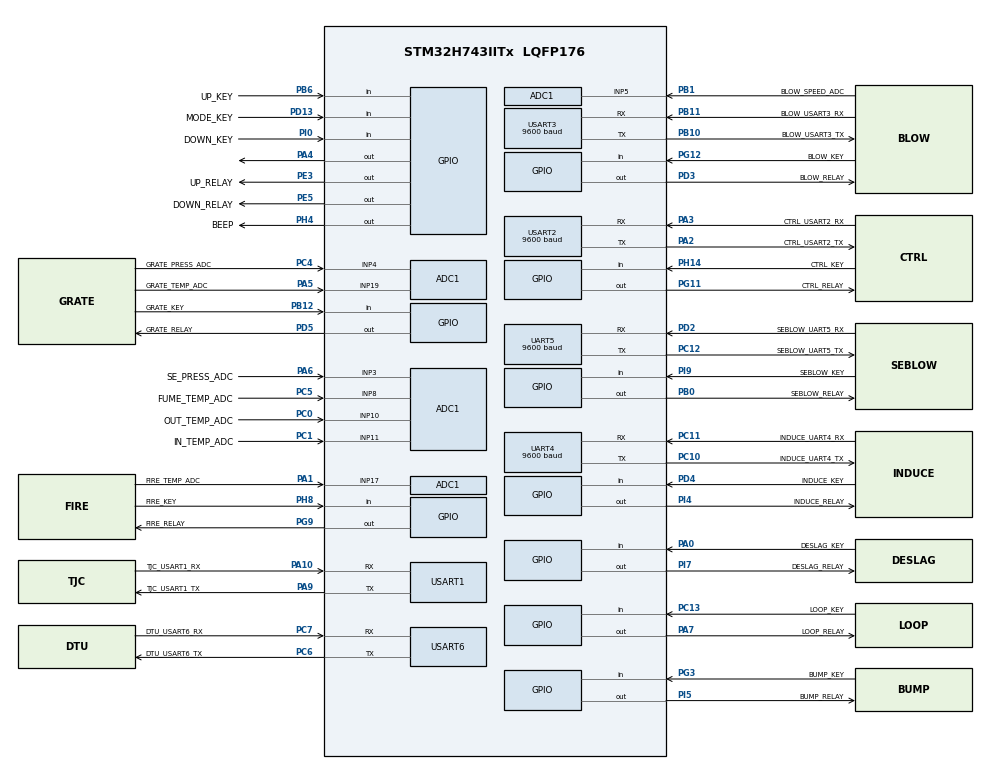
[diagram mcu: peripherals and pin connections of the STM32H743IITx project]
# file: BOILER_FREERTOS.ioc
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ADC1.Channel-0\#ChannelRegularConversion=ADC_CHANNEL_11
ADC1.NbrOfConversionFlag=1
ADC1.OffsetNumber-0\#ChannelRegularConversion=ADC_OFFSET_NONE
ADC1.OffsetSignedSaturation-0\#ChannelRegularConversion=DISABLE
ADC1.Rank-0\#ChannelRegularConversion=1
ADC1.SamplingTime-0\#ChannelRegularConversion=ADC_SAMPLETIME_1CYCLE_5
ADC1.master=1
CORTEX_M7.default_mode_Activation=1
Mcu.Family=STM32H7
Mcu.Name=STM32H743IITx
Mcu.Package=LQFP176
NVIC.PriorityGroup=NVIC_PRIORITYGROUP_4
NVIC.TIM4_IRQn=true\:15\:0\:false\:false\:true\:false\:true\:true
NVIC.TimeBase=TIM4_IRQn
NVIC.TimeBaseIP=TIM4
PA0.GPIO_Label=DESLAG_KEY
PA0.GPIO_PuPd=GPIO_PULLUP
PA0.Signal=GPIO_Input
PA1.GPIO_Label=FIRE_TEMP_ADC
PA1.Mode=IN17-Single-Ended
PA1.Signal=ADC1_INP17
PA10.GPIO_Label=TJC_USART1_RX
PA10.Mode=Asynchronous
PA10.Signal=USART1_RX
PA13\ (JTMS/SWDIO).Mode=Serial_Wire
PA13\ (JTMS/SWDIO).Signal=DEBUG_JTMS-SWDIO
PA14\ (JTCK/SWCLK).Mode=Serial_Wire
PA14\ (JTCK/SWCLK).Signal=DEBUG_JTCK-SWCLK
PA2.GPIO_Label=CTRL_USART2_TX
PA2.Mode=Asynchronous
PA2.Signal=USART2_TX
PA3.GPIO_Label=CTRL_USART2_RX
PA3.Mode=Asynchronous
PA3.Signal=USART2_RX
PA4.Signal=GPIO_Output
PA5.GPIO_Label=GRATE_TEMP_ADC
PA5.Signal=ADCx_INP19
PA6.GPIO_Label=SE_PRESS_ADC
PA6.Signal=ADCx_INP3
PA7.GPIO_Label=LOOP_RELAY
PA7.GPIO_PuPd=GPIO_PULLDOWN
PA7.Signal=GPIO_Output
PA9.GPIO_Label=TJC_USART1_TX
PA9.Mode=Asynchronous
PA9.Signal=USART1_TX
PB0.GPIO_Label=SEBLOW_RELAY
PB0.GPIO_PuPd=GPIO_PULLDOWN
PB0.Signal=GPIO_Output
PB1.GPIO_Label=BLOW_SPEED_ADC
PB1.Signal=ADCx_INP5
PB10.GPIO_Label=BLOW_USART3_TX
PB10.Mode=Asynchronous
PB10.Signal=USART3_TX
PB11.GPIO_Label=BLOW_USART3_RX
PB11.Mode=Asynchronous
PB11.Signal=USART3_RX
PB12.GPIO_Label=GRATE_KEY
PB12.GPIO_PuPd=GPIO_PULLUP
PB12.Signal=GPIO_Input
PB6.GPIO_Label=UP_KEY
PB6.GPIO_PuPd=GPIO_PULLUP
PB6.Signal=GPIO_Input
PB8.GPIO_Label=AT24CXX_SCL
PB8.Signal=I2C1_SCL
PB9.GPIO_Label=AT24CXX_SDA
PB9.Signal=I2C1_SDA
PC0.GPIO_Label=OUT_TEMP_ADC
PC0.Signal=ADCx_INP10
PC1.GPIO_Label=IN_TEMP_ADC
PC1.Signal=ADCx_INP11
PC10.GPIO_Label=INDUCE_UART4_TX
PC10.Mode=Asynchronous
PC10.Signal=UART4_TX
PC11.GPIO_Label=INDUCE_UART4_RX
PC11.Mode=Asynchronous
PC11.Signal=UART4_RX
PC12.GPIO_Label=SEBLOW_UART5_TX
PC12.Mode=Asynchronous
PC12.Signal=UART5_TX
PC13.GPIO_Label=LOOP_KEY
PC13.GPIO_PuPd=GPIO_PULLUP
PC13.Signal=GPIO_Input
PC14-OSC32_IN\ (OSC32_IN).Mode=LSE-External-Oscillator
PC14-OSC32_IN\ (OSC32_IN).Signal=RCC_OSC32_IN
PC15-OSC32_OUT\ (OSC32_OUT).Mode=LSE-External-Oscillator
PC15-OSC32_OUT\ (OSC32_OUT).Signal=RCC_OSC32_OUT
PC4.GPIO_Label=GRATE_PRESS_ADC
PC4.Signal=ADCx_INP4
PC5.GPIO_Label=FUME_TEMP_ADC
PC5.Signal=ADCx_INP8
PC6.GPIO_Label=DTU_USART6_TX
PC6.Mode=Asynchronous
PC6.Signal=USART6_TX
PC7.GPIO_Label=DTU_USART6_RX
PC7.Mode=Asynchronous
PC7.Signal=USART6_RX
PD13.GPIO_Label=MODE_KEY
PD13.GPIO_PuPd=GPIO_PULLUP
PD13.Signal=GPIO_Input
PD2.GPIO_Label=SEBLOW_UART5_RX
PD2.Mode=Asynchronous
PD2.Signal=UART5_RX
PD3.GPIO_Label=BLOW_RELAY
PD3.GPIO_PuPd=GPIO_PULLDOWN
PD3.Signal=GPIO_Output
PD4.GPIO_Label=INDUCE_KEY
PD4.GPIO_PuPd=GPIO_PULLUP
PD4.Signal=GPIO_Input
PD5.GPIO_Label=GRATE_RELAY
PD5.GPIO_PuPd=GPIO_PULLDOWN
PD5.Signal=GPIO_Output
PE3.GPIO_Label=UP_RELAY
PE3.GPIO_PuPd=GPIO_PULLDOWN
PE3.Signal=GPIO_Output
PE5.GPIO_Label=DOWN_RELAY
PE5.GPIO_PuPd=GPIO_PULLDOWN
PE5.Signal=GPIO_Output
PG11.GPIO_Label=CTRL_RELAY
PG11.GPIO_PuPd=GPIO_PULLDOWN
PG11.Signal=GPIO_Output
PG12.GPIO_Label=BLOW_KEY
PG12.GPIO_PuPd=GPIO_PULLUP
PG12.Signal=GPIO_Input
PG3.GPIO_Label=BUMP_KEY
PG3.GPIO_PuPd=GPIO_PULLUP
PG3.Signal=GPIO_Input
PG9.GPIO_Label=FIRE_RELAY
PG9.GPIO_PuPd=GPIO_PULLDOWN
PG9.Signal=GPIO_Output
PH0-OSC_IN\ (PH0).Mode=HSE-External-Oscillator
PH0-OSC_IN\ (PH0).Signal=RCC_OSC_IN
PH1-OSC_OUT\ (PH1).Mode=HSE-External-Oscillator
PH1-OSC_OUT\ (PH1).Signal=RCC_OSC_OUT
PH14.GPIO_Label=CTRL_KEY
PH14.GPIO_PuPd=GPIO_PULLUP
PH14.Signal=GPIO_Input
PH4.GPIO_Label=BEEP
PH4.GPIO_PuPd=GPIO_PULLDOWN
PH4.GPIO_Speed=GPIO_SPEED_FREQ_MEDIUM
PH4.Signal=GPIO_Output
PH8.GPIO_Label=FIRE_KEY
PH8.GPIO_PuPd=GPIO_PULLUP
PH8.Signal=GPIO_Input
PI0.GPIO_Label=DOWN_KEY
PI0.GPIO_PuPd=GPIO_PULLUP
PI0.Signal=GPIO_Input
PI4.GPIO_Label=INDUCE_RELAY
PI4.GPIO_PuPd=GPIO_PULLDOWN
PI4.Signal=GPIO_Output
PI5.GPIO_Label=BUMP_RELAY
PI5.GPIO_PuPd=GPIO_PULLDOWN
PI5.Signal=GPIO_Output
PI7.GPIO_Label=DESLAG_RELAY
PI7.GPIO_PuPd=GPIO_PULLDOWN
PI7.Signal=GPIO_Output
PI9.GPIO_Label=SEBLOW_KEY
PI9.GPIO_PuPd=GPIO_PULLUP
PI9.Signal=GPIO_Input
ProjectManager.HeapSize=0x200
ProjectManager.StackSize=0x400
ProjectManager.TargetToolchain=MDK-ARM V5.32
RCC.ADCFreq_Value=75000000
RCC.APB1Freq_Value=100000000
RCC.APB2Freq_Value=100000000
RCC.APB3Freq_Value=100000000
RCC.APB4Freq_Value=100000000
RCC.CortexFreq_Value=400000000
RCC.D1PPRE=RCC_APB3_DIV2
RCC.D2PPRE1=RCC_APB1_DIV2
RCC.D2PPRE2=RCC_APB2_DIV2
RCC.D3PPRE=RCC_APB4_DIV2
RCC.DIVM1=2
RCC.DIVM2=2
RCC.DIVN1=64
RCC.DIVN2=12
RCC.HCLKFreq_Value=200000000
RCC.HPRE=RCC_HCLK_DIV2
RCC.PLL2FRACN=0
RCC.PLLFRACN=0
RCC.PLLSourceVirtual=RCC_PLLSOURCE_HSE
RCC.SYSCLKFreq_VALUE=400000000
RCC.SYSCLKSource=RCC_SYSCLKSOURCE_PLLCLK
RCC.USBFreq_Value=400000000
SH.ADCx_INP10.0=ADC1_INP10,IN10-Single-Ended
SH.ADCx_INP11.0=ADC1_INP11,IN11-Single-Ended
SH.ADCx_INP19.0=ADC1_INP19,IN19-Single-Ended
SH.ADCx_INP3.0=ADC1_INP3,IN3-Single-Ended
SH.ADCx_INP4.0=ADC1_INP4,IN4-Single-Ended
SH.ADCx_INP5.0=ADC1_INP5,IN5-Single-Ended
SH.ADCx_INP8.0=ADC1_INP8,IN8-Single-Ended
UART4.BaudRate=9600
UART5.BaudRate=9600
USART1.VirtualMode-Asynchronous=VM_ASYNC
USART2.BaudRate=9600
USART2.VirtualMode-Asynchronous=VM_ASYNC
USART3.BaudRate=9600
USART3.VirtualMode-Asynchronous=VM_ASYNC
USART6.VirtualMode-Asynchronous=VM_ASYNC
VP_MEMORYMAP_VS_MEMORYMAP.Mode=CurAppReg
VP_SYS_VS_tim4.Mode=TIM4
board=custom

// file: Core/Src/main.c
/* USER CODE BEGIN Header */
/**
  ******************************************************************************
  * @file           : main.c
  * @brief          : Main program body
  ******************************************************************************
  * @attention
  *
  * Copyright (c) 2026 STMicroelectronics.
  * All rights reserved.
  *
  * This software is licensed under terms that can be found in the LICENSE file
  * in the root directory of this software component.
  * If no LICENSE file comes with this software, it is provided AS-IS.
  *
  ******************************************************************************
  */
/* USER CODE END Header */
#include "main.h"
#include "adc.h"
#include "memorymap.h"
#include "usart.h"
#include "gpio.h"

/* USER CODE BEGIN Includes */
#include "app_freertos.h"
/* USER CODE END Includes */

void SystemClock_Config(void);
static void MPU_Config(void);

int main(void)
{

  /* MPU Configuration--------------------------------------------------------*/
  MPU_Config();

  /* MCU Configuration--------------------------------------------------------*/

  /* Reset of all peripherals, Initializes the Flash interface and the Systick. */
  HAL_Init();

  /* Configure the system clock */
  SystemClock_Config();

  /* Initialize all configured peripherals */
  MX_GPIO_Init();
  MX_ADC1_Init();
  MX_UART4_Init();
  MX_UART5_Init();
  MX_USART1_UART_Init();
  MX_USART2_UART_Init();
  MX_USART3_UART_Init();
  MX_USART6_UART_Init();

  /* Infinite loop */
  while (1)
  {

  }
}

void SystemClock_Config(void)
{
  RCC_OscInitTypeDef RCC_OscInitStruct = {0};
  RCC_ClkInitTypeDef RCC_ClkInitStruct = {0};

  /** Supply configuration update enable
  */
  HAL_PWREx_ConfigSupply(PWR_LDO_SUPPLY);

  /** Configure the main internal regulator output voltage
  */
  __HAL_PWR_VOLTAGESCALING_CONFIG(PWR_REGULATOR_VOLTAGE_SCALE1);

  while(!__HAL_PWR_GET_FLAG(PWR_FLAG_VOSRDY)) {}

  /** Initializes the RCC Oscillators according to the specified parameters
  * in the RCC_OscInitTypeDef structure.
  */
  RCC_OscInitStruct.OscillatorType = RCC_OSCILLATORTYPE_HSE;
  RCC_OscInitStruct.HSEState = RCC_HSE_ON;
  RCC_OscInitStruct.PLL.PLLState = RCC_PLL_ON;
  RCC_OscInitStruct.PLL.PLLSource = RCC_PLLSOURCE_HSE;
  RCC_OscInitStruct.PLL.PLLM = 2;
  RCC_OscInitStruct.PLL.PLLN = 64;
  RCC_OscInitStruct.PLL.PLLP = 2;
  RCC_OscInitStruct.PLL.PLLQ = 2;
  RCC_OscInitStruct.PLL.PLLR = 2;
  RCC_OscInitStruct.PLL.PLLRGE = RCC_PLL1VCIRANGE_3;
  RCC_OscInitStruct.PLL.PLLVCOSEL = RCC_PLL1VCOWIDE;
  RCC_OscInitStruct.PLL.PLLFRACN = 0;
  if (HAL_RCC_OscConfig(&RCC_OscInitStruct) != HAL_OK)
  {
    Error_Handler();
  }

  /** Initializes the CPU, AHB and APB buses clocks
  */
  RCC_ClkInitStruct.ClockType = RCC_CLOCKTYPE_HCLK|RCC_CLOCKTYPE_SYSCLK
                              |RCC_CLOCKTYPE_PCLK1|RCC_CLOCKTYPE_PCLK2
                              |RCC_CLOCKTYPE_D3PCLK1|RCC_CLOCKTYPE_D1PCLK1;
  RCC_ClkInitStruct.SYSCLKSource = RCC_SYSCLKSOURCE_PLLCLK;
  RCC_ClkInitStruct.SYSCLKDivider = RCC_SYSCLK_DIV1;
  RCC_ClkInitStruct.AHBCLKDivider = RCC_HCLK_DIV2;
  RCC_ClkInitStruct.APB3CLKDivider = RCC_APB3_DIV2;
  RCC_ClkInitStruct.APB1CLKDivider = RCC_APB1_DIV2;
  RCC_ClkInitStruct.APB2CLKDivider = RCC_APB2_DIV2;
  RCC_ClkInitStruct.APB4CLKDivider = RCC_APB4_DIV2;

  if (HAL_RCC_ClockConfig(&RCC_ClkInitStruct, FLASH_LATENCY_2) != HAL_OK)
  {
    Error_Handler();
  }
}

 /* MPU Configuration */

void MPU_Config(void)
{
  MPU_Region_InitTypeDef MPU_InitStruct = {0};

  /* Disables the MPU */
  HAL_MPU_Disable();

  /** Initializes and configures the Region and the memory to be protected
  */
  MPU_InitStruct.Enable = MPU_REGION_ENABLE;
  MPU_InitStruct.Number = MPU_REGION_NUMBER0;
  MPU_InitStruct.BaseAddress = 0x0;
  MPU_InitStruct.Size = MPU_REGION_SIZE_4GB;
  MPU_InitStruct.SubRegionDisable = 0x87;
  MPU_InitStruct.TypeExtField = MPU_TEX_LEVEL0;
  MPU_InitStruct.AccessPermission = MPU_REGION_NO_ACCESS;
  MPU_InitStruct.DisableExec = MPU_INSTRUCTION_ACCESS_DISABLE;
  MPU_InitStruct.IsShareable = MPU_ACCESS_SHAREABLE;
  MPU_InitStruct.IsCacheable = MPU_ACCESS_NOT_CACHEABLE;
  MPU_InitStruct.IsBufferable = MPU_ACCESS_NOT_BUFFERABLE;

  HAL_MPU_ConfigRegion(&MPU_InitStruct);
  /* Enables the MPU */
  HAL_MPU_Enable(MPU_PRIVILEGED_DEFAULT);

}

void HAL_TIM_PeriodElapsedCallback(TIM_HandleTypeDef *htim)
{
  if (htim->Instance == TIM4) {
    HAL_IncTick();
  }
}

void Error_Handler(void)
{
  __disable_irq();
  while (1)
  {
  }
}
